# STM32G431xx register map
File version: 1.9
CPU: CM4 r0p1, little endian, MPU, FPU, 4 interrupt priority bits
Registers are 32-bit, read-write, reset 0x0 unless marked. A register's access mark holds for its fields unless they carry their own. Offsets are from the block's base; [hi:lo] are bit positions; {n}, {i} and the like mark numbered series; 'fields as' and 'values as' point back to an identical list; <NAME> marks a mode.

## RCC (part 1 of 2) — Reset and clock control
Base 0x40021000
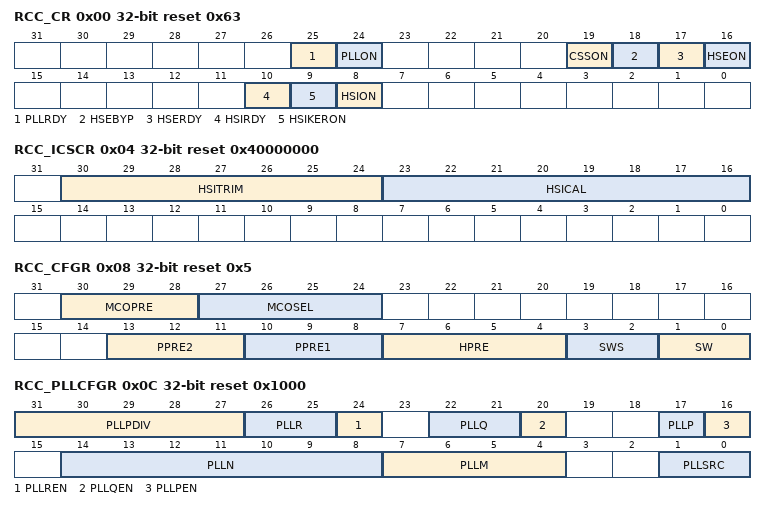
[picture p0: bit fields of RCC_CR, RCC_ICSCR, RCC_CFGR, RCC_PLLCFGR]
0x00 RCC_CR access per field reset 0x63 — Clock control register
  [25] PLLRDY ro — Main PLL clock ready flag Set by hardware to indicate that the main PLL is locked.
    0=PLL unlocked; 1=PLL locked
  [24] PLLON rw — Main PLL enable Set and cleared by software to enable the main PLL. Cleared by hardware when entering Stop, Standby or Shutdown mode. This bit cannot be reset if the PLL clock is used as the system clock.
    0=PLL OFF; 1=PLL ON
  [19] CSSON rw — Clock security system enable Set by software to enable the clock security system. When CSSON is set, the clock detector is enabled by hardware when the HSE oscillator is ready, and disabled by hardware if a HSE clock failure is detected. This bit is set only and is cleared by reset.
    0=Clock security system OFF (clock detector OFF); 1=Clock security system ON (Clock detector ON if the HSE oscillator is stable, OFF if not)
  [18] HSEBYP rw — HSE crystal oscillator bypass Set and cleared by software to bypass the oscillator with an external clock. The external clock must be enabled with the HSEON bit set, to be used by the device. The HSEBYP bit can be written only if the HSE oscillator is disabled.
    0=HSE crystal oscillator not bypassed; 1=HSE crystal oscillator bypassed with external clock
  [17] HSERDY ro — HSE clock ready flag Set by hardware to indicate that the HSE oscillator is stable. Note: Once the HSEON bit is cleared, HSERDY goes low after 6 HSE clock cycles.
    0=HSE oscillator not ready; 1=HSE oscillator ready
  [16] HSEON rw — HSE clock enable Set and cleared by software. Cleared by hardware to stop the HSE oscillator when entering Stop, Standby or Shutdown mode. This bit cannot be reset if the HSE oscillator is used directly or indirectly as the system clock.
    0=HSE oscillator OFF; 1=HSE oscillator ON
  [10] HSIRDY ro — HSI16 clock ready flag Set by hardware to indicate that HSI16 oscillator is stable. This bit is set only when HSI16 is enabled by software by setting HSION. Note: Once the HSION bit is cleared, HSIRDY goes low after 6 HSI16 clock cycles.
    0=HSI16 oscillator not ready; 1=HSI16 oscillator ready
  [9] HSIKERON rw — HSI16 always enable for peripheral kernels. Set and cleared by software to force HSI16 ON even in Stop modes. The HSI16 can only feed USARTs and I<sup>2</sup>Cs peripherals configured with HSI16 as kernel clock. Keeping the HSI16 ON in Stop mode allows to avoid slowing down the communication speed because of the HSI16 startup time. This bit has no effect on HSION value.
    0=No effect on HSI16 oscillator; 1=HSI16 oscillator is forced ON even in Stop mode
  [8] HSION rw — HSI16 clock enable Set and cleared by software. Cleared by hardware to stop the HSI16 oscillator when entering Stop, Standby or Shutdown mode. Set by hardware to force the HSI16 oscillator ON when STOPWUCK=1 or HSIASFS = 1 when leaving Stop modes, or in case of failure of the HSE crystal oscillator. This bit is set by hardware if the HSI16 is used directly or indirectly as system clock.
    0=HSI16 oscillator OFF; 1=HSI16 oscillator ON
0x04 RCC_ICSCR access per field reset 0x40000000 — Internal clock sources calibration register
  [30:24] HSITRIM rw — HSI16 clock trimming These bits provide an additional user-programmable trimming value that is added to the HSICAL[7:0] bits. It can be programmed to adjust to variations in voltage and temperature that influence the frequency of the HSI16. The default value is 16, which, when added to the HSICAL value, should trim the HSI16 to 16 MHz � 1 %.
  [23:16] HSICAL ro — HSI16 clock calibration These bits are initialized at startup with the factory-programmed HSI16 calibration trim value. When HSITRIM is written, HSICAL is updated with the sum of HSITRIM and the factory trim value.
0x08 RCC_CFGR access per field reset 0x5 — Clock configuration register
  [30:28] MCOPRE rw — Microcontroller clock output prescaler These bits are set and cleared by software. It is highly recommended to change this prescaler before MCO output is enabled. Others: not allowed
    0=MCO is divided by 1; 1=MCO is divided by 2; 2=MCO is divided by 4; 3=MCO is divided by 8; 4=MCO is divided by 16
  [27:24] MCOSEL rw — Microcontroller clock output Set and cleared by software. Others: Reserved Note: This clock output may have some truncated cycles at startup or during MCO clock source switching.
    0=MCO output disabled, no clock on MCO; 1=SYSCLK system clock selected; 2=Reserved, must be kept at reset value; 3=HSI16 clock selected; 4=HSE clock selected; 5=Main PLL clock selected; 6=LSI clock selected; 7=LSE clock selected; 8=Internal HSI48 clock selected
  [13:11] PPRE2 rw — APB2 prescaler Set and cleared by software to control the division factor of the APB2 clock (PCLK2). 0xx: HCLK not divided
    4=HCLK divided by 2; 5=HCLK divided by 4; 6=HCLK divided by 8; 7=HCLK divided by 16
  [10:8] PPRE1 rw — APB1 prescaler Set and cleared by software to control the division factor of the APB1 clock (PCLK1). 0xx: HCLK not divided
    values as PPRE2
  [7:4] HPRE rw — AHB prescaler Set and cleared by software to control the division factor of the AHB clock. Note: Depending on the device voltage range, the software has to set correctly these bits to ensure that the system frequency does not exceed the maximum allowed frequency (for more details please refer to Section 6.1.5: Dynamic voltage scaling management). After a write operation to these bits and before decreasing the voltage range, this register must be read to be sure that the new value has been taken into account. 0xxx: SYSCLK not divided
    8=SYSCLK divided by 2; 9=SYSCLK divided by 4; 10=SYSCLK divided by 8; 11=SYSCLK divided by 16; 12=SYSCLK divided by 64; 13=SYSCLK divided by 128; 14=SYSCLK divided by 256; 15=SYSCLK divided by 512
  [3:2] SWS ro — System clock switch status Set and cleared by hardware to indicate which clock source is used as system clock.
    0=Reserved, must be kept at reset value; 1=HSI16 oscillator used as system clock; 2=HSE used as system clock; 3=PLL used as system clock
  [1:0] SW rw — System clock switch Set and cleared by software to select system clock source (SYSCLK). Configured by hardware to force HSI16 oscillator selection when exiting stop and standby modes or in case of failure of the HSE oscillator.
    0=Reserved, must be kept at reset value; 1=HSI16 selected as system clock; 2=HSE selected as system clock; 3=PLL selected as system clock
0x0C RCC_PLLCFGR reset 0x1000 — PLL configuration register
  [31:27] PLLPDIV — Main PLLP division factor Set and cleared by software to control the PLL “P” frequency. PLL “P” output clock frequency = VCO frequency / PLLPDIV. ....
    0=PLL “P” clock is controlled by the bit PLLP; 2=PLL “P” clock = VCO / 2; 31=PLL “P” clock = VCO / 31
  [26:25] PLLR — Main PLL division factor for PLL “R” clock (system clock) Set and cleared by software to control the frequency of the main PLL output clock PLLCLK. This output can be selected as system clock. These bits can be written only if PLL is disabled. PLL “R” output clock frequency = VCO frequency / PLLR with PLLR = 2, 4, 6, or 8 Note: The software has to set these bits correctly not to exceed 170 MHz on this domain.
    0=PLLR = 2; 1=PLLR = 4; 2=PLLR = 6; 3=PLLR = 8
  [24] PLLREN — PLL “R” clock output enable Set and reset by software to enable the PLL “R” clock output of the PLL (used as system clock). This bit cannot be written when PLL “R” clock output of the PLL is used as System Clock. In order to save power, when the PLL “R” clock output of the PLL is not used, the value of PLLREN should be 0.
    0=PLL “R” clock output disable; 1=PLL “R” clock output enable
  [22:21] PLLQ — Main PLL division factor for PLL “Q” clock. Set and cleared by software to control the frequency of the main PLL output clock PLL “Q” clock. This output can be selected for USB, RNG, SAI (48 MHz clock). These bits can be written only if PLL is disabled. PLL “Q” output clock frequency = VCO frequency / PLLQ with PLLQ = 2, 4, 6, or 8 Note: The software has to set these bits correctly not to exceed 170 MHz on this domain.
    0=PLLQ = 2; 1=PLLQ = 4; 2=PLLQ = 6; 3=PLLQ = 8
  [20] PLLQEN — Main PLL “Q” clock output enable Set and reset by software to enable the PLL “Q” clock output of the PLL. In order to save power, when the PLL “Q” clock output of the PLL is not used, the value of PLLQEN should be 0.
    0=PLL “Q” clock output disable; 1=PLL “Q” clock output enable
  [17] PLLP — Main PLL division factor for PLL “P” clock. Set and cleared by software to control the frequency of the main PLL output clock PLL “P” clock. These bits can be written only if PLL is disabled. When the PLLPDIV[4:0] is set to “00000”PLL “P” output clock frequency = VCO frequency / PLLP with PLLP =7, or 17 Note: The software has to set these bits correctly not to exceed 170 MHz on this domain.
    0=PLLP = 7; 1=PLLP = 17
  [16] PLLPEN — Main PLL PLL “P” clock output enable Set and reset by software to enable the PLL “P” clock output of the PLL. In order to save power, when the PLL “P” clock output of the PLL is not used, the value of PLLPEN should be 0.
    0=PLL “P” clock output disable; 1=PLL “P” clock output enable
  [14:8] PLLN — Main PLL multiplication factor for VCO Set and cleared by software to control the multiplication factor of the VCO. These bits can be written only when the PLL is disabled. VCO output frequency = VCO input frequency x PLLN with 8 =< PLLN =< 127 ... ... Note: The software has to set correctly these bits to assure that the VCO output frequency is within the range defined in the device datasheet.
    0=PLLN = 0 wrong configuration; 1=PLLN = 1 wrong configuration; 7=PLLN = 7 wrong configuration; 8=PLLN = 8; 9=PLLN = 9; 127=PLLN = 127
  [7:4] PLLM — Division factor for the main PLL input clock Set and cleared by software to divide the PLL input clock before the VCO. These bits can be written only when all PLLs are disabled. VCO input frequency = PLL input clock frequency / PLLM with 1 <= PLLM <= 16 ... Note: The software has to set these bits correctly to ensure that the VCO input frequency is within the range defined in the device datasheet.
    {v}=PLLM = {v+1} (v=0..7); 8=PLLSYSM = 9; 15=PLLSYSM= 16
  [1:0] PLLSRC — Main PLL entry clock source Set and cleared by software to select PLL clock source. These bits can be written only when PLL is disabled. In order to save power, when no PLL is used, the value of PLLSRC should be 00.
    0=No clock sent to PLL; 1=No clock sent to PLL; 2=HSI16 clock selected as PLL clock entry; 3=HSE clock selected as PLL clock entry
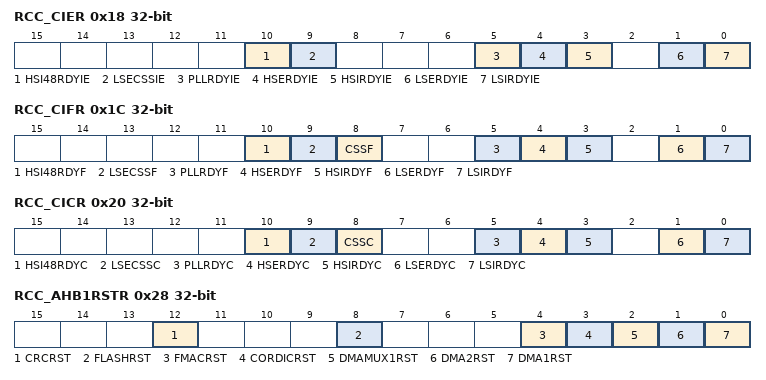
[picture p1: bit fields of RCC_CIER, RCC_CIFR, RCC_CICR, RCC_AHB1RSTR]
0x18 RCC_CIER — Clock interrupt enable register
  [10] HSI48RDYIE — HSI48 ready interrupt enable Set and cleared by software to enable/disable interrupt caused by the internal HSI48 oscillator.
    0=HSI48 ready interrupt disabled; 1=HSI48 ready interrupt enabled
  [9] LSECSSIE — LSE clock security system interrupt enable Set and cleared by software to enable/disable interrupt caused by the clock security system on LSE.
    0=Clock security interrupt caused by LSE clock failure disabled; 1=Clock security interrupt caused by LSE clock failure enabled
  [5] PLLRDYIE — PLL ready interrupt enable Set and cleared by software to enable/disable interrupt caused by PLL lock.
    0=PLL lock interrupt disabled; 1=PLL lock interrupt enabled
  [4] HSERDYIE — HSE ready interrupt enable Set and cleared by software to enable/disable interrupt caused by the HSE oscillator stabilization.
    0=HSE ready interrupt disabled; 1=HSE ready interrupt enabled
  [3] HSIRDYIE — HSI16 ready interrupt enable Set and cleared by software to enable/disable interrupt caused by the HSI16 oscillator stabilization.
    0=HSI16 ready interrupt disabled; 1=HSI16 ready interrupt enabled
  [1] LSERDYIE — LSE ready interrupt enable Set and cleared by software to enable/disable interrupt caused by the LSE oscillator stabilization.
    0=LSE ready interrupt disabled; 1=LSE ready interrupt enabled
  [0] LSIRDYIE — LSI ready interrupt enable Set and cleared by software to enable/disable interrupt caused by the LSI oscillator stabilization.
    0=LSI ready interrupt disabled; 1=LSI ready interrupt enabled
0x1C RCC_CIFR ro — Clock interrupt flag register
  [10] HSI48RDYF — HSI48 ready interrupt flag Set by hardware when the HSI48 clock becomes stable and HSI48RDYIE is set in a response to setting the HSI48ON (refer to Clock recovery RC register (RCC_CRRCR)). Cleared by software setting the HSI48RDYC bit.
    0=No clock ready interrupt caused by the HSI48 oscillator; 1=Clock ready interrupt caused by the HSI48 oscillator
  [9] LSECSSF — LSE Clock security system interrupt flag Set by hardware when a failure is detected in the LSE oscillator. Cleared by software setting the LSECSSC bit.
    0=No clock security interrupt caused by LSE clock failure; 1=Clock security interrupt caused by LSE clock failure
  [8] CSSF — Clock security system interrupt flag Set by hardware when a failure is detected in the HSE oscillator. Cleared by software setting the CSSC bit.
    0=No clock security interrupt caused by HSE clock failure; 1=Clock security interrupt caused by HSE clock failure
  [5] PLLRDYF — PLL ready interrupt flag Set by hardware when the PLL locks and PLLRDYDIE is set. Cleared by software setting the PLLRDYC bit.
    0=No clock ready interrupt caused by PLL lock; 1=Clock ready interrupt caused by PLL lock
  [4] HSERDYF — HSE ready interrupt flag Set by hardware when the HSE clock becomes stable and HSERDYDIE is set. Cleared by software setting the HSERDYC bit.
    0=No clock ready interrupt caused by the HSE oscillator; 1=Clock ready interrupt caused by the HSE oscillator
  [3] HSIRDYF — HSI16 ready interrupt flag Set by hardware when the HSI16 clock becomes stable and HSIRDYDIE is set in a response to setting the HSION (refer to Clock control register (RCC_CR)). When HSION is not set but the HSI16 oscillator is enabled by the peripheral through a clock request, this bit is not set and no interrupt is generated. Cleared by software setting the HSIRDYC bit.
    0=No clock ready interrupt caused by the HSI16 oscillator; 1=Clock ready interrupt caused by the HSI16 oscillator
  [1] LSERDYF — LSE ready interrupt flag Set by hardware when the LSE clock becomes stable and LSERDYDIE is set. Cleared by software setting the LSERDYC bit.
    0=No clock ready interrupt caused by the LSE oscillator; 1=Clock ready interrupt caused by the LSE oscillator
  [0] LSIRDYF — LSI ready interrupt flag Set by hardware when the LSI clock becomes stable and LSIRDYDIE is set. Cleared by software setting the LSIRDYC bit.
    0=No clock ready interrupt caused by the LSI oscillator; 1=Clock ready interrupt caused by the LSI oscillator
0x20 RCC_CICR wo — Clock interrupt clear register
  [10] HSI48RDYC — HSI48 oscillator ready interrupt clear This bit is set by software to clear the HSI48RDYF flag.
    0=No effect; 1=Clear the HSI48RDYC flag
  [9] LSECSSC — LSE Clock security system interrupt clear This bit is set by software to clear the LSECSSF flag.
    0=No effect; 1=Clear LSECSSF flag
  [8] CSSC — Clock security system interrupt clear This bit is set by software to clear the CSSF flag.
    0=No effect; 1=Clear CSSF flag
  [5] PLLRDYC — PLL ready interrupt clear This bit is set by software to clear the PLLRDYF flag.
    0=No effect; 1=Clear PLLRDYF flag
  [4] HSERDYC — HSE ready interrupt clear This bit is set by software to clear the HSERDYF flag.
    0=No effect; 1=Clear HSERDYF flag
  [3] HSIRDYC — HSI16 ready interrupt clear This bit is set software to clear the HSIRDYF flag.
    0=No effect; 1=Clear HSIRDYF flag
  [1] LSERDYC — LSE ready interrupt clear This bit is set by software to clear the LSERDYF flag.
    0=No effect; 1=LSERDYF cleared
  [0] LSIRDYC — LSI ready interrupt clear This bit is set by software to clear the LSIRDYF flag.
    0=No effect; 1=LSIRDYF cleared
0x28 RCC_AHB1RSTR — AHB1 peripheral reset register
  [12] CRCRST — CRC reset Set and cleared by software.
    0=No effect; 1=Reset CRC
  [8] FLASHRST — Flash memory interface reset Set and cleared by software. This bit can be activated only when the Flash memory is in power down mode.
    0=No effect; 1=Reset Flash memory interface
  [4] FMACRST — Set and cleared by software
    0=No effect; 1=Reset FMAC
  [3] CORDICRST — Set and cleared by software
    0=No effect; 1=Reset CORDIC
  [2] DMAMUX1RST — Set and cleared by software.
    0=No effect; 1=Reset DMAMUX1
  [1] DMA2RST — DMA2 reset Set and cleared by software.
    0=No effect; 1=Reset DMA2
  [0] DMA1RST — DMA1 reset Set and cleared by software.
    0=No effect; 1=Reset DMA1
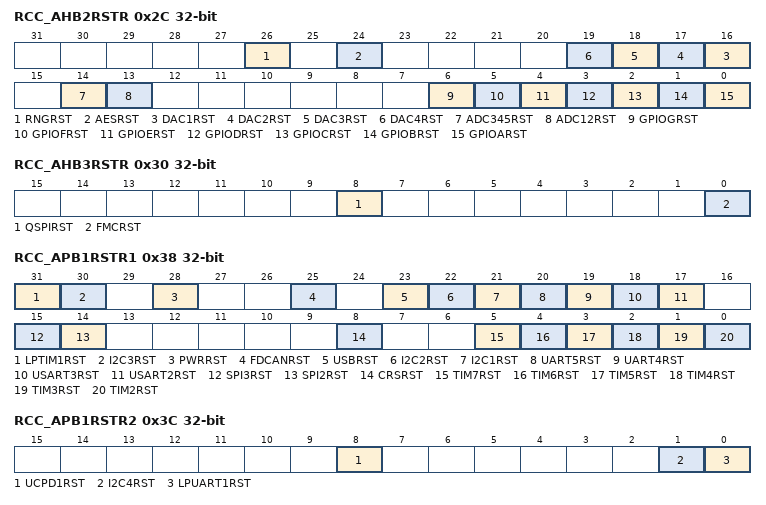
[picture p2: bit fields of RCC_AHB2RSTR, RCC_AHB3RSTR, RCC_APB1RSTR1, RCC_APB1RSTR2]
0x2C RCC_AHB2RSTR — AHB2 peripheral reset register
  [26] RNGRST — RNG reset Set and cleared by software.
    0=No effect; 1=Reset RNG
  [24] AESRST — AESRST reset Set and cleared by software.
    0=No effect; 1=Reset AES
  [n+15] DAC{n}RST (n=1..4) — DAC{n} reset Set and cleared by software.
    0=No effect; 1=Reset DAC{n}
  [14] ADC345RST — ADC345 reset Set and cleared by software.
    0=No effect; 1=Reset ADC345
  [13] ADC12RST — ADC12 reset Set and cleared by software.
    0=No effect; 1=Reset ADC12 interface
  [6] GPIOGRST — IO port G reset Set and cleared by software.
    0=No effect; 1=Reset IO port G
  [5] GPIOFRST — IO port F reset Set and cleared by software.
    0=No effect; 1=Reset IO port F
  [4] GPIOERST — IO port E reset Set and cleared by software.
    0=No effect; 1=Reset IO port E
  [3] GPIODRST — IO port D reset Set and cleared by software.
    0=No effect; 1=Reset IO port D
  [2] GPIOCRST — IO port C reset Set and cleared by software.
    0=No effect; 1=Reset IO port C
  [1] GPIOBRST — IO port B reset Set and cleared by software.
    0=No effect; 1=Reset IO port B
  [0] GPIOARST — IO port A reset Set and cleared by software.
    0=No effect; 1=Reset IO port A
0x30 RCC_AHB3RSTR — AHB3 peripheral reset register
  [8] QSPIRST — QUADSPI reset Set and cleared by software.
    0=No effect; 1=Reset QUADSPI
  [0] FMCRST — Flexible static memory controller reset Set and cleared by software.
    0=No effect; 1=Reset FSMC
0x38 RCC_APB1RSTR1 — APB1 peripheral reset register 1
  [31] LPTIM1RST — Low Power Timer 1 reset Set and cleared by software.
    0=No effect; 1=Reset LPTIM1
  [30] I2C3RST — I2C3 reset Set and cleared by software.
    0=No effect; 1=Reset I2C3 interface
  [28] PWRRST — Power interface reset Set and cleared by software.
    0=No effect; 1=Reset PWR
  [25] FDCANRST — FDCAN reset Set and reset by software.
    0=No effect; 1=Reset the FDCAN
  [23] USBRST — USB device reset Set and reset by software.
    0=No effect; 1=Reset USB device
  [22] I2C2RST — I2C2 reset Set and cleared by software.
    0=No effect; 1=Reset I2C2
  [21] I2C1RST — I2C1 reset Set and cleared by software.
    0=No effect; 1=Reset I2C1
  [20] UART5RST — UART5 reset Set and cleared by software.
    0=No effect; 1=Reset UART5
  [19] UART4RST — UART4 reset Set and cleared by software.
    0=No effect; 1=Reset UART4
  [18] USART3RST — USART3 reset Set and cleared by software.
    0=No effect; 1=Reset USART3
  [17] USART2RST — USART2 reset Set and cleared by software.
    0=No effect; 1=Reset USART2
  [15] SPI3RST — SPI3 reset Set and cleared by software.
    0=No effect; 1=Reset SPI3
  [14] SPI2RST — SPI2 reset Set and cleared by software.
    0=No effect; 1=Reset SPI2
  [8] CRSRST — CRS reset Set and cleared by software.
    0=No effect; 1=Reset CRS
  [5] TIM7RST — TIM7 timer reset Set and cleared by software.
    0=No effect; 1=Reset TIM7
  [4] TIM6RST — TIM6 timer reset Set and cleared by software.
    0=No effect; 1=Reset TIM7
  [3] TIM5RST — TIM5 timer reset Set and cleared by software.
    0=No effect; 1=Reset TIM5
  [2] TIM4RST — TIM3 timer reset Set and cleared by software.
    0=No effect; 1=Reset TIM3
  [1] TIM3RST — TIM3 timer reset Set and cleared by software.
    0=No effect; 1=Reset TIM3
  [0] TIM2RST — TIM2 timer reset Set and cleared by software.
    0=No effect; 1=Reset TIM2
0x3C RCC_APB1RSTR2 — APB1 peripheral reset register 2
  [8] UCPD1RST — UCPD1 reset Set and cleared by software.
    0=No effect; 1=Reset UCPD1
  [1] I2C4RST — I2C4 reset Set and cleared by software
    0=No effect; 1=Reset I2C4
  [0] LPUART1RST — Low-power UART 1 reset Set and cleared by software.
    0=No effect; 1=Reset LPUART1
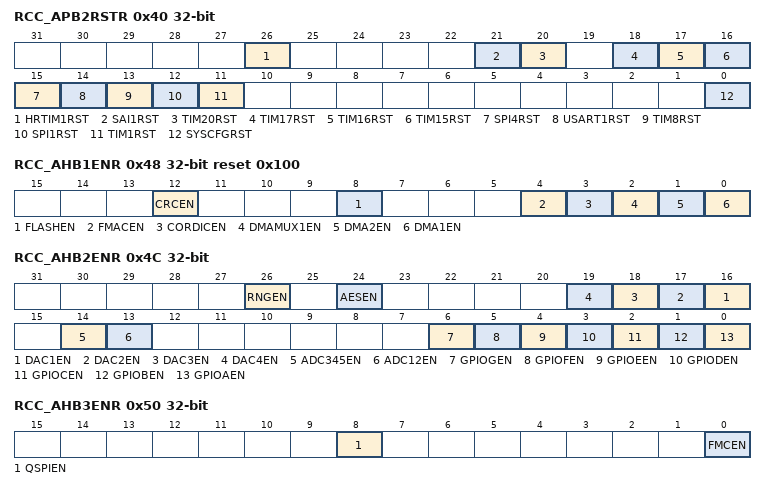
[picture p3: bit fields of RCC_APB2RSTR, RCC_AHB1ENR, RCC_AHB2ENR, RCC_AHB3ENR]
0x40 RCC_APB2RSTR — APB2 peripheral reset register
  [26] HRTIM1RST — HRTIM1 reset Set and cleared by software.
    0=No effect; 1=Reset HRTIM1
  [21] SAI1RST — Serial audio interface 1 (SAI1) reset Set and cleared by software.
    0=No effect; 1=Reset SAI1
  [20] TIM20RST — TIM20 reset Set and cleared by software.
    0=No effect; 1=Reset TIM20
  [18] TIM17RST — TIM17 timer reset Set and cleared by software.
    0=No effect; 1=Reset TIM17 timer
  [17] TIM16RST — TIM16 timer reset Set and cleared by software.
    0=No effect; 1=Reset TIM16 timer
  [16] TIM15RST — TIM15 timer reset Set and cleared by software.
    0=No effect; 1=Reset TIM15 timer
  [15] SPI4RST — SPI4 reset Set and cleared by software.
    0=No effect; 1=Reset SPI4
  [14] USART1RST — USART1 reset Set and cleared by software.
    0=No effect; 1=Reset USART1
  [13] TIM8RST — TIM8 timer reset Set and cleared by software.
    0=No effect; 1=Reset TIM8 timer
  [12] SPI1RST — SPI1 reset Set and cleared by software.
    0=No effect; 1=Reset SPI1
  [11] TIM1RST — TIM1 timer reset Set and cleared by software.
    0=No effect; 1=Reset TIM1 timer
  [0] SYSCFGRST — SYSCFG + COMP + OPAMP + VREFBUF reset
    0=No effect; 1=Reset SYSCFG + COMP + OPAMP + VREFBUF
0x48 RCC_AHB1ENR reset 0x100 — AHB1 peripheral clock enable register
  [12] CRCEN — CRC clock enable Set and cleared by software.
    0=CRC clock disable; 1=CRC clock enable
  [8] FLASHEN — Flash memory interface clock enable Set and cleared by software. This bit can be disabled only when the Flash is in power down mode.
    0=Flash memory interface clock disable; 1=Flash memory interface clock enable
  [4] FMACEN — FMAC enable Set and reset by software.
    0=FMAC clock disabled; 1=FMAC clock enabled
  [3] CORDICEN — CORDIC clock enable Set and reset by software.
    0=CORDIC clock disabled; 1=CORDIC clock enabled
  [2] DMAMUX1EN — DMAMUX1 clock enable Set and reset by software.
    0=DMAMUX1 clock disabled; 1=DMAMUX1 clock enabled
  [1] DMA2EN — DMA2 clock enable Set and cleared by software.
    0=DMA2 clock disable; 1=DMA2 clock enable
  [0] DMA1EN — DMA1 clock enable Set and cleared by software.
    0=DMA1 clock disable; 1=DMA1 clock enable
0x4C RCC_AHB2ENR — AHB2 peripheral clock enable register
  [26] RNGEN — RNG enable Set and cleared by software.
    0=RNG disabled; 1=RNG enabled
  [24] AESEN — AES clock enable Set and cleared by software.
    0=AES clock disabled; 1=AES clock enabled
  [n+15] DAC{n}EN (n=1..4) — DAC{n} clock enable Set and cleared by software.
    0=DAC{n} clock disabled; 1=DAC{n} clock enabled
  [14] ADC345EN — ADC345 clock enable Set and cleared by software
    0=ADC345 clock disabled; 1=ADC345 clock enabled
  [13] ADC12EN — ADC12 clock enable Set and cleared by software.
    0=ADC12 clock disabled; 1=ADC12 clock enabled
  [6] GPIOGEN — IO port G clock enable Set and cleared by software.
    0=IO port G clock disabled; 1=IO port G clock enabled
  [5] GPIOFEN — IO port F clock enable Set and cleared by software.
    0=IO port F clock disabled; 1=IO port F clock enabled
  [4] GPIOEEN — IO port E clock enable Set and cleared by software.
    0=IO port E clock disabled; 1=IO port E clock enabled
  [3] GPIODEN — IO port D clock enable Set and cleared by software.
    0=IO port D clock disabled; 1=IO port D clock enabled
  [2] GPIOCEN — IO port C clock enable Set and cleared by software.
    0=IO port C clock disabled; 1=IO port C clock enabled
  [1] GPIOBEN — IO port B clock enable Set and cleared by software.
    0=IO port B clock disabled; 1=IO port B clock enabled
  [0] GPIOAEN — IO port A clock enable Set and cleared by software.
    0=IO port A clock disabled; 1=IO port A clock enabled
0x50 RCC_AHB3ENR — AHB3 peripheral clock enable register
  [8] QSPIEN — QUADSPI memory interface clock enable Set and cleared by software.
    0=QUADSPI clock disable; 1=QUADSPI clock enable
  [0] FMCEN — Flexible static memory controller clock enable Set and cleared by software.
    0=FSMC clock disable; 1=FSMC clock enable
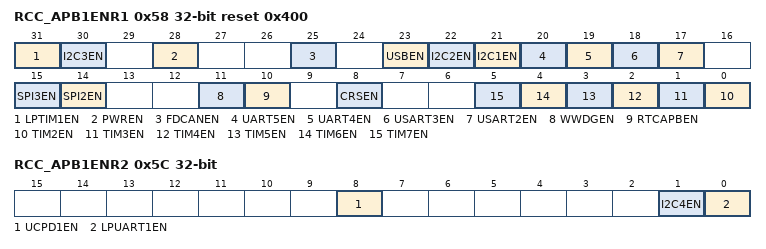
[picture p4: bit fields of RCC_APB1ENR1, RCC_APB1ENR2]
0x58 RCC_APB1ENR1 reset 0x400 — APB1 peripheral clock enable register 1
  [31] LPTIM1EN — Low power timer 1 clock enable Set and cleared by software.
    0=LPTIM1 clock disabled; 1=LPTIM1 clock enabled
  [30] I2C3EN — I2C3 clock enable Set and cleared by software.
    0=I2C3 clock disabled; 1=I2C3 clock enabled
  [28] PWREN — Power interface clock enable Set and cleared by software.
    0=Power interface clock disabled; 1=Power interface clock enabled
  [25] FDCANEN — FDCAN clock enable Set and cleared by software.
    0=FDCAN clock disabled; 1=FDCAN clock enabled
  [23] USBEN — USB device clock enable Set and cleared by software.
    0=USB device clock disabled; 1=USB device clock enabled
  [22] I2C2EN — I2C2 clock enable Set and cleared by software.
    0=I2C2 clock disabled; 1=I2C2 clock enabled
  [21] I2C1EN — I2C1 clock enable Set and cleared by software.
    0=I2C1 clock disabled; 1=I2C1 clock enabled
  [20] UART5EN — UART5 clock enable Set and cleared by software.
    0=UART5 clock disabled; 1=UART5 clock enabled
  [19] UART4EN — UART4 clock enable Set and cleared by software.
    0=UART4 clock disabled; 1=UART4 clock enabled
  [18] USART3EN — USART3 clock enable Set and cleared by software.
    0=USART3 clock disabled; 1=USART3 clock enabled
  [17] USART2EN — USART2 clock enable Set and cleared by software.
    0=USART2 clock disabled; 1=USART2 clock enabled
  [15] SPI3EN — SPI3 clock enable Set and cleared by software.
    0=SPI3 clock disabled; 1=SPI3 clock enabled
  [14] SPI2EN — SPI2 clock enable Set and cleared by software.
    0=SPI2 clock disabled; 1=SPI2 clock enabled
  [11] WWDGEN — Window watchdog clock enable Set by software to enable the window watchdog clock. Reset by hardware system reset. This bit can also be set by hardware if the WWDG_SW option bit is reset.
    0=Window watchdog clock disabled; 1=Window watchdog clock enabled
  [10] RTCAPBEN — RTC APB clock enable Set and cleared by software
    0=RTC APB clock disabled; 1=RTC APB clock enabled
  [8] CRSEN — CRS Recovery System clock enable Set and cleared by software.
    0=CRS clock disabled; 1=CRS clock enabled
  [n-2] TIM{n}EN (n=2..7) — TIM{n} timer clock enable Set and cleared by software.
    0=TIM{n} clock disabled; 1=TIM{n} clock enabled
0x5C RCC_APB1ENR2 — APB1 peripheral clock enable register 2
  [8] UCPD1EN — UCPD1 clock enable Set and cleared by software.
    0=UCPD1 clock disable; 1=UCPD1 clock enable
  [1] I2C4EN — I2C4 clock enable Set and cleared by software
    0=I2C4 clock disabled; 1=I2C4 clock enabled
  [0] LPUART1EN — Low power UART 1 clock enable Set and cleared by software.
    0=LPUART1 clock disable; 1=LPUART1 clock enable

## Notices in the file
Copyright (c) 2022 STMicroelectronics.
SPDX-License-Identifier: Apache-2.0
Licensed under the Apache License, Version 2.0 (the "License");
you may not use this file except in compliance with the License.
You may obtain a copy of the License at
http://www.apache.org/licenses/LICENSE-2.0
Unless required by applicable law or agreed to in writing, software
distributed under the License is distributed on an "AS IS" BASIS,
WITHOUT WARRANTIES OR CONDITIONS OF ANY KIND, either express or implied.
See the License for the specific language governing permissions and
limitations under the License.
